# MIK32 register map
Vendor: Mikron JSC; Series: MIK32; File version: 1.0
Registers are 32-bit, read-write, reset 0x0 unless marked. A register's access mark holds for its fields unless they carry their own. Offsets are from the block's base; [hi:lo] are bit positions; {n}, {i} and the like mark numbered series; 'fields as' and 'values as' point back to an identical list.

## PVD_VCC — Управление монитором напряжения VCC
Base 0x00051800
Same registers: PVD_AVCC 0x00085010
0x00 DPF_VALUE reset 0x5DC — Настройка цифрового фильтра
  [15:0] DPF — Коэффициент, определяющий длительность отфильтровываемых импульсов (на системной частоте)
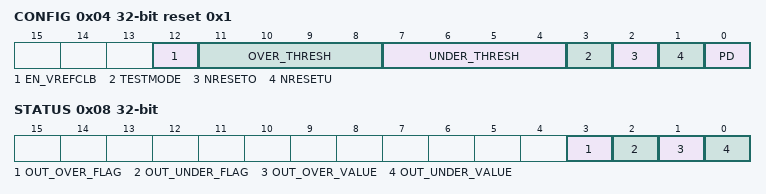
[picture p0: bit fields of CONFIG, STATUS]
0x04 CONFIG reset 0x1 — Регистр настроек
  [12] EN_VREFCLB — Использование в качестве источника опорного напряжения калибруемый ИОН
  [11:8] OVER_THRESH — Верхний порог срабатывания монитора
  [7:4] UNDER_THRESH — Нижний порог срабатывания монитора
  [3] TESTMODE — Переход в тестовый режим
  [2] NRESETO — Отключение (сброс) детектирования вехнего порога
    0=Reset (Детектирование не выполняется, схема в состоянии сброса); 1=Normal (Нормальная работа)
  [1] NRESETU — Отключение (сброс) детектирования нижнего порога
    values as NRESETO
  [0] PD — Управление питанием монитора
    0=Enable (Монитор включен); 1=Disable (Монитор выключен)
0x08 STATUS ro — Регистр статуса
  [3] OUT_OVER_FLAG — Текущее состояние линии монитора верхнего порога с учетом цифровой фильтрации
  [2] OUT_UNDER_FLAG — Текущее состояние линии монитора нижнего порога с учетом цифровой фильтрации
  [1] OUT_OVER_VALUE — Текущее состояние линии монитора верхнего порога без цифровой фильтрации
  [0] OUT_UNDER_VALUE — Текущее состояние линии монитора нижнего порога без цифровой фильтрации

## PAD_CONFIG — Модуль управления функцией ввода/вывода
Base 0x00050C00
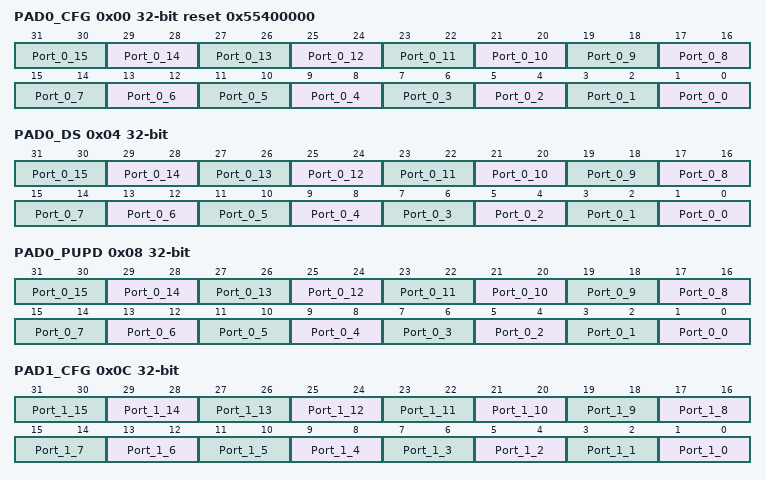
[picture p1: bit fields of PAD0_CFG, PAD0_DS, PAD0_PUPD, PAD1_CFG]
0x00 PAD0_CFG reset 0x55400000 — Управление функциями выводов PORT0
  [all] fields
    0=Func1_GPIO (Первая функция (порт общего назначения)); 1=Func2_interface (Вторая функция (последовательный интерфейс)); 2=Func3_interface_or_timer (Третья функция (последовательный интерфейс или таймер)); 3=Func4_Analog (Четвертая функция (аналоговый сигнал))
  [2n+1:2n] Port_0_{n} (n=0..15) — Значения двух бит кодируют выбранный функционал для вывода
0x04 PAD0_DS — Управление нагрузочной способностью выводов PORT0
  [all] fields
    0=2mA (Нагрузочная способность вывода 2 мА); 1=4mA (Нагрузочная способность вывода 4 мА); 2=8mA (Нагрузочная способность вывода 8 мА)
  [2n+1:2n] Port_0_{n} (n=0..15) — Значения двух бит кодируют выбранный режим для вывода
0x08 PAD0_PUPD — Управление резисторами подтяжки выводов PORT0
  [all] fields
    0=Pull_none (Без подтяжки); 1=Pull_up (Подтяжка к питанию); 2=Pull_down (Подтяжка к земле)
  [2n+1:2n] Port_0_{n} (n=0..15) — Значения двух бит кодируют выбранный режим для вывода
0x0C PAD1_CFG — Управление функциями выводов PORT1
  [all] fields
    values as the fields of PAD0_CFG
  [2n+1:2n] Port_1_{n} (n=0..15) — Значения двух бит кодируют выбранный функционал для вывода
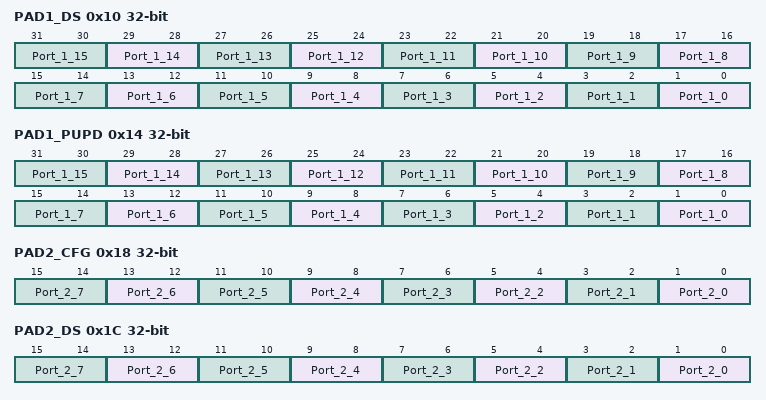
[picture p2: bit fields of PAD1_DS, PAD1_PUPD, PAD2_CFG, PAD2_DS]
0x10 PAD1_DS — Управление нагрузочной способностью выводов PORT1
  [all] fields
    values as the fields of PAD0_DS
  [2n+1:2n] Port_1_{n} (n=0..15) — Значения двух бит кодируют выбранный режим для вывода
0x14 PAD1_PUPD — Управление резисторами подтяжки выводов PORT1
  [all] fields
    values as the fields of PAD0_PUPD
  [2n+1:2n] Port_1_{n} (n=0..15) — Значения двух бит кодируют выбранный режим для вывода
0x18 PAD2_CFG — Управление функциями выводов PORT2
  [all] fields
    values as the fields of PAD0_CFG
  [2n+1:2n] Port_2_{n} (n=0..7) — Значения двух бит кодируют выбранный функционал для вывода
0x1C PAD2_DS — Управление нагрузочной способностью выводов PORT2
  [all] fields
    values as the fields of PAD0_DS
  [2n+1:2n] Port_2_{n} (n=0..7) — Значения двух бит кодируют выбранный режим для вывода
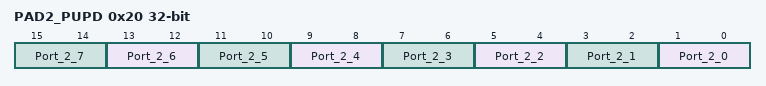
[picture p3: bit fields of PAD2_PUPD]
0x20 PAD2_PUPD — Управление резисторами подтяжки выводов PORT2
  [all] fields
    values as the fields of PAD0_PUPD
  [2n+1:2n] Port_2_{n} (n=0..7) — Значения двух бит кодируют выбранный режим для вывода

## WDT_BUS — Сторожевой таймер шины
Base 0x00051000
0x00 TIMEOUT — Определеяет количество циклов ожидания до формирования ошибки. Значения от 0 до 15. Количество циклов ожидания вычисляется как 2^TIMEOUT.
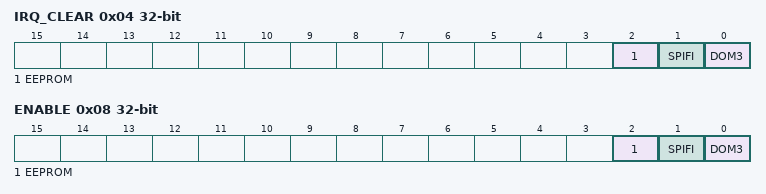
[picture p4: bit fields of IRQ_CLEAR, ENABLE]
0x04 IRQ_CLEAR wo write-1-clears — Сброс прерываний
  [2] EEPROM write-1-clears — Сброс прерываний для монитора шины EEPROM
  [1] SPIFI write-1-clears — Сброс прерываний для монитора шины SPIFI
  [0] DOM3 write-1-clears — Сброс прерываний для монитора шины периферийных устройств
0x08 ENABLE — Запуск/отключение мониторов шины
  [all] fields
    0=Disable (Монитор шины выключен); 1=Enable (Монитор шины включен)
  [2] EEPROM — Управление монитором шины EEPROM
  [1] SPIFI — Управление монитором шины SPIFI
  [0] DOM3 — Управление монитором шины периферийных устройств
